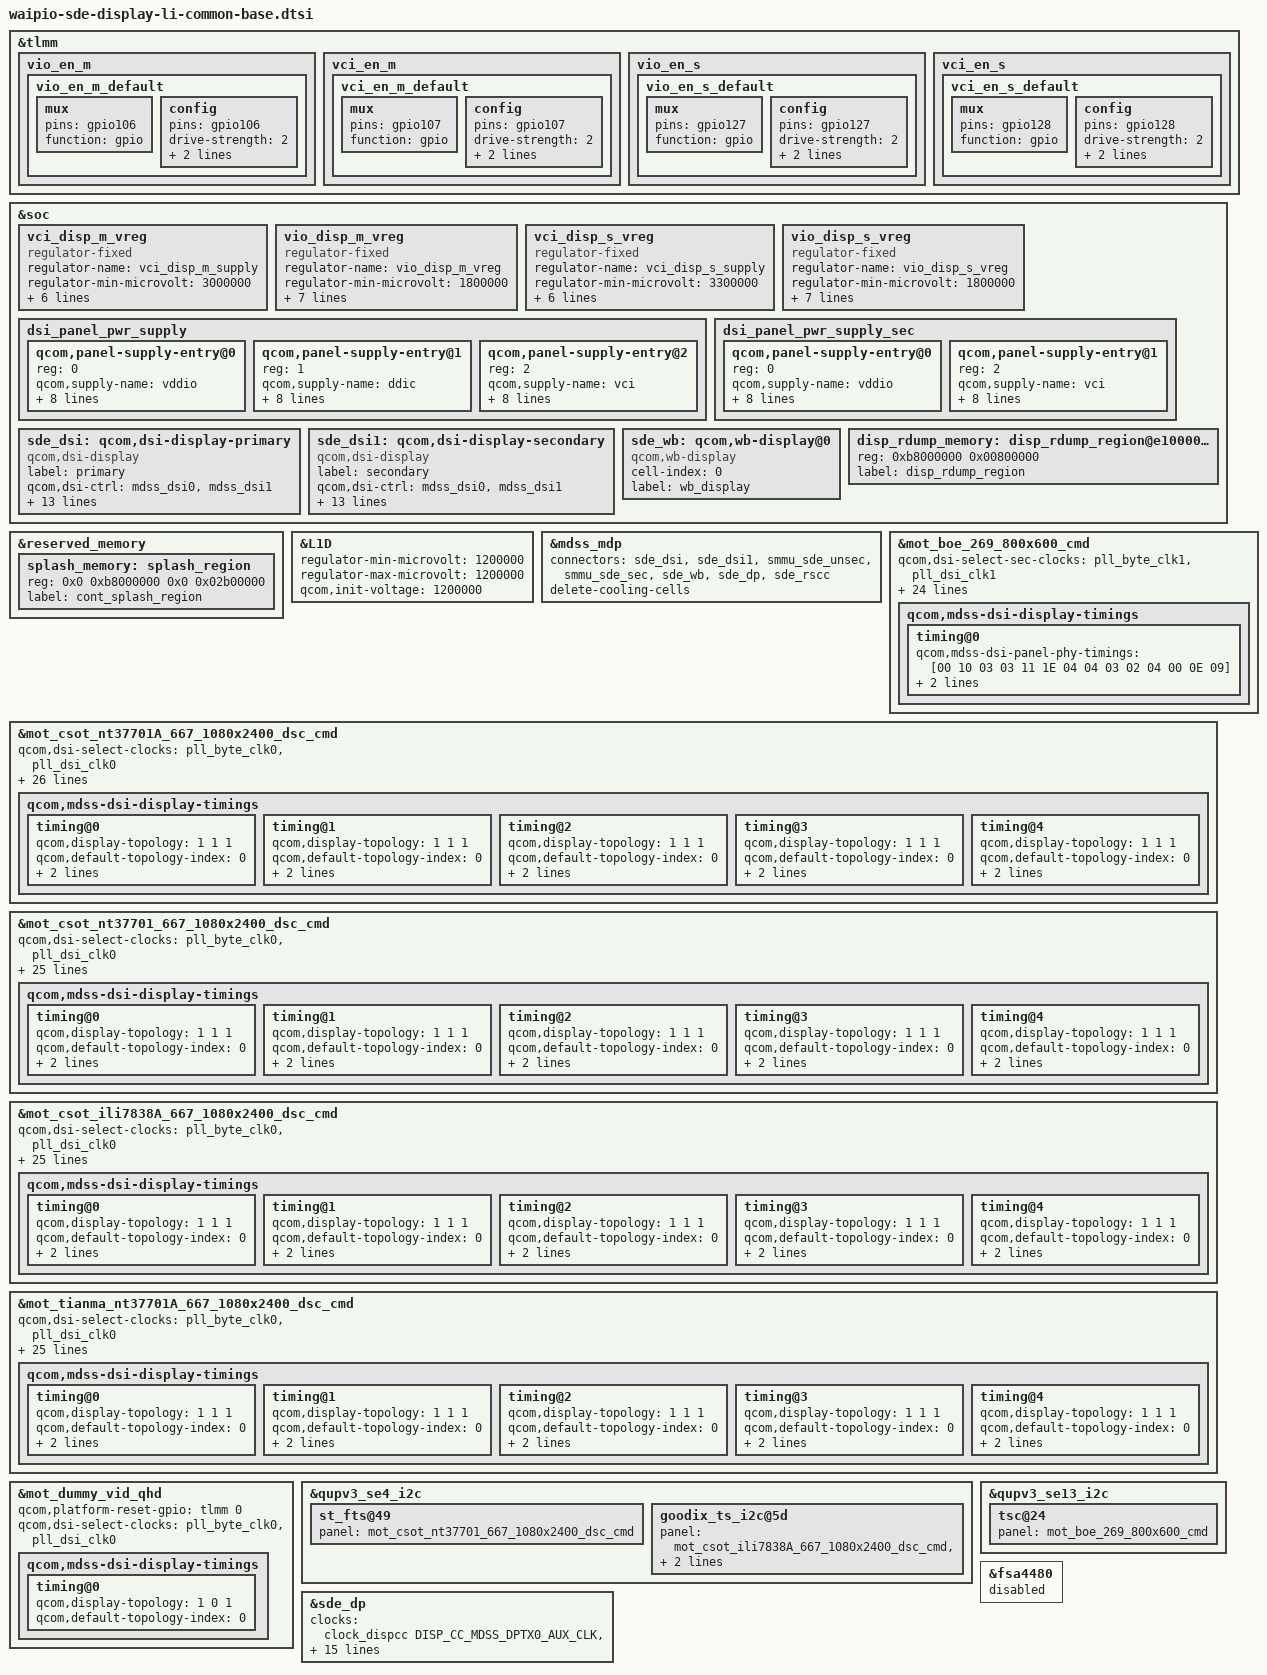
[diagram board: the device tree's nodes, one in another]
/*
   this is original from waipio-sde-display-hiphi-common-base.dtsi
*/
#include <dt-bindings/clock/qcom,gcc-waipio.h>
#include <dt-bindings/clock/qcom,rpmh.h>
#include "waipio-sde-display-pinctrl.dtsi"
#include "dsi-panel-mot-dummy-qhd-video.dtsi"
#include <dt-bindings/clock/qcom,dispcc-waipio.h>
#include "dsi-panel-mot-csot-nt37701-667-1080x2400-dsc-cmd-common.dtsi"
#include "dsi-panel-mot-csot-ili7838A-667-1080x2400-dsc-cmd-common.dtsi"
#include "dsi-panel-mot-tianma-nt37701A-667-1080x2400-dsc-cmd-common.dtsi"
#include "dsi-panel-mot-csot-nt37701A-667-1080x2400-dsc-cmd-common.dtsi"
#include "dsi-panel-mot-boe-269-800x600-cmd-common.dtsi"

&tlmm {
	vio_en_m {
		vio_en_m_default: vio_en_m_default {
			mux {
				pins = "gpio106";
				function = "gpio";
			};

			config {
				pins = "gpio106";
				drive-strength = <2>;   /* 2 mA */
				bias-disable = <0>;   /* no pull */
				output-high;
			};
		};
	};
	vci_en_m {
		vci_en_m_default: vci_en_m_default {
			mux {
				pins = "gpio107";
				function = "gpio";
			};

			config {
				pins = "gpio107";
				drive-strength = <2>;   /* 2 mA */
				bias-disable = <0>;   /* no pull */
				output-enable;
			};
		};
	};
	vio_en_s {
		vio_en_s_default: vio_en_s_default {
			mux {
				pins = "gpio127";
				function = "gpio";
			};

			config {
				pins = "gpio127";
				drive-strength = <2>;   /* 2 mA */
				bias-disable = <0>;   /* no pull */
				output-high;
			};
		};
	};
	vci_en_s {
		vci_en_s_default: vci_en_s_default {
			mux {
				pins = "gpio128";
				function = "gpio";
			};

			config {
				pins = "gpio128";
				drive-strength = <2>;   /* 2 mA */
				bias-disable = <0>;   /* no pull */
				output-enable;
			};
		};
	};
};

&soc {
	vci_disp_m_vreg:  vci_disp_m_vreg{
		compatible = "regulator-fixed";
		regulator-name = "vci_disp_m_supply";
		regulator-min-microvolt = <3000000>;
		regulator-max-microvolt = <3000000>;
		enable-active-high;
		regulator-boot-on;

		gpio = <&tlmm 107 0>;
		pinctrl-names = "default";
		pinctrl-0 = <&vci_en_m_default>;
		vin-supply = <&L13C>;
	};

	vio_disp_m_vreg: vio_disp_m_vreg{
		compatible = "regulator-fixed";
		regulator-name = "vio_disp_m_vreg";
		regulator-min-microvolt = <1800000>;
		regulator-max-microvolt = <1800000>;
		regulator-enable-ramp-delay = <233>;
		enable-active-high;
		regulator-boot-on;

		gpio = <&tlmm 106 0>;
		pinctrl-names = "default";
		pinctrl-0 = <&vio_en_m_default>;
		vin-supply = <&L12C>;
	};

	vci_disp_s_vreg:  vci_disp_s_vreg{
		compatible = "regulator-fixed";
		regulator-name = "vci_disp_s_supply";
		regulator-min-microvolt = <3300000>;
		regulator-max-microvolt = <3300000>;
		enable-active-high;
		regulator-boot-on;

		gpio = <&tlmm 128 0>;
		pinctrl-names = "default";
		pinctrl-0 = <&vci_en_s_default>;
		vin-supply = <&L3C>;
	};

	vio_disp_s_vreg: vio_disp_s_vreg{
		compatible = "regulator-fixed";
		regulator-name = "vio_disp_s_vreg";
		regulator-min-microvolt = <1800000>;
		regulator-max-microvolt = <1800000>;
		regulator-enable-ramp-delay = <233>;
		enable-active-high;
		regulator-boot-on;

		gpio = <&tlmm 127 0>;
		pinctrl-names = "default";
		pinctrl-0 = <&vio_en_s_default>;
		vin-supply = <&L2C>;
	};


	dsi_panel_pwr_supply: dsi_panel_pwr_supply {
		#address-cells = <1>;
		#size-cells = <0>;

	qcom,panel-supply-entry@0 {
		reg = <0>;
		qcom,supply-name = "vddio";
		qcom,supply-min-voltage = <1800000>;
		qcom,supply-max-voltage = <1800000>;
		qcom,supply-enable-load = <300000>;
		qcom,supply-disable-load = <100>;
		qcom,supply-pre-on-sleep = <0>;
		qcom,supply-post-on-sleep = <1>;
		qcom,supply-pre-off-sleep = <3>;
		qcom,supply-post-off-sleep = <0>;
        };

        qcom,panel-supply-entry@1 {
		reg = <1>;
		qcom,supply-name = "ddic";
		qcom,supply-min-voltage = <1200000>;
		qcom,supply-max-voltage = <1200000>;
		qcom,supply-enable-load = <300000>;
		qcom,supply-disable-load = <0>;
		qcom,supply-pre-on-sleep = <1>;
		qcom,supply-post-on-sleep = <0>;
		qcom,supply-pre-off-sleep = <2>;
		qcom,supply-post-off-sleep = <0>;
        };
        qcom,panel-supply-entry@2 {
		reg = <2>;
		qcom,supply-name = "vci";
		qcom,supply-min-voltage = <3000000>;
		qcom,supply-max-voltage = <3000000>;
		qcom,supply-enable-load = <300000>;
		qcom,supply-disable-load = <0>;
		qcom,supply-pre-on-sleep = <0>;
		qcom,supply-post-on-sleep = <0>;
		qcom,supply-pre-off-sleep = <2>;
		qcom,supply-post-off-sleep = <0>;
        };
	};

	dsi_panel_pwr_supply_sec: dsi_panel_pwr_supply_sec {
		#address-cells = <1>;
		#size-cells = <0>;

	qcom,panel-supply-entry@0 {
		reg = <0>;
		qcom,supply-name = "vddio";
		qcom,supply-min-voltage = <1800000>;
		qcom,supply-max-voltage = <1800000>;
		qcom,supply-enable-load = <300000>;
		qcom,supply-disable-load = <100>;
		qcom,supply-pre-on-sleep = <0>;
		qcom,supply-post-on-sleep = <1>;
		qcom,supply-pre-off-sleep = <3>;
		qcom,supply-post-off-sleep = <0>;
        };

        qcom,panel-supply-entry@1 {
		reg = <2>;
		qcom,supply-name = "vci";
		qcom,supply-min-voltage = <3300000>;
		qcom,supply-max-voltage = <3300000>;
		qcom,supply-enable-load = <300000>;
		qcom,supply-disable-load = <0>;
		qcom,supply-pre-on-sleep = <0>;
		qcom,supply-post-on-sleep = <0>;
		qcom,supply-pre-off-sleep = <2>;
		qcom,supply-post-off-sleep = <0>;
        };
	};
	sde_dsi: qcom,dsi-display-primary {
		compatible = "qcom,dsi-display";
		label = "primary";

		qcom,dsi-ctrl = <&mdss_dsi0 &mdss_dsi1>;
		qcom,dsi-phy = <&mdss_dsi_phy0 &mdss_dsi_phy1>;

		pinctrl-names = "panel_active", "panel_suspend";
		pinctrl-0 = <&sde_dsi_active &sde_te_active>;
		pinctrl-1 = <&sde_dsi_suspend &sde_te_suspend>;

		qcom,platform-te-gpio = <&tlmm 86 0>;
		qcom,panel-te-source = <0>;

		qcom,mdp = <&mdss_mdp>;
		qcom,dsi-default-panel = <&mot_dummy_vid_qhd>;
	};

	sde_dsi1: qcom,dsi-display-secondary {
		compatible = "qcom,dsi-display";
		label = "secondary";

		qcom,dsi-ctrl = <&mdss_dsi0 &mdss_dsi1>;
		qcom,dsi-phy = <&mdss_dsi_phy0 &mdss_dsi_phy1>;

		pinctrl-names = "panel_active", "panel_suspend";
		pinctrl-0 = <&sde_dsi1_active &sde_te1_active>;
		pinctrl-1 = <&sde_dsi1_suspend &sde_te1_suspend>;

		qcom,platform-te-gpio = <&tlmm 124 0>;
		qcom,panel-te-source = <1>;

		qcom,mdp = <&mdss_mdp>;
		qcom,dsi-default-panel = <&mot_boe_269_800x600_cmd>;
	};
};


&soc {
	/*display_panel_avdd: display_gpio_regulator@1 {
		compatible = "qti-regulator-fixed";
		regulator-name = "display_panel_avdd";
		regulator-min-microvolt = <5500000>;
		regulator-max-microvolt = <5500000>;
		regulator-enable-ramp-delay = <233>;
		gpio = <&tlmm 64 0>;
		enable-active-high;
		regulator-boot-on;
		proxy-supply = <&display_panel_avdd>;
		qcom,proxy-consumer-enable;
		pinctrl-names = "default";
		pinctrl-0 = <&display_panel_avdd_default>;
	};*/

	sde_wb: qcom,wb-display@0 {
		compatible = "qcom,wb-display";
		cell-index = <0>;
		label = "wb_display";
	};

	disp_rdump_memory: disp_rdump_region@e1000000 {
		reg = <0xb8000000 0x00800000>;
		label = "disp_rdump_region";
	};

};

&reserved_memory {
	splash_memory: splash_region {
		reg = <0x0 0xb8000000 0x0 0x02b00000>;
		label = "cont_splash_region";
	};
};

&sde_dsi {
	clocks = <&mdss_dsi_phy0 0>,
			<&mdss_dsi_phy0 1>,
			<&mdss_dsi_phy1 2>,
			<&mdss_dsi_phy1 3>,
			 /*
			  * Currently the dsi clock handles are under the dsi
			  * controller DT node. As soon as the controller probe
			  * finishes, the dispcc sync state can get called before
			  * the dsi_display probe potentially disturbing the clock
			  * votes for cont_splash use case. Hence we are no longer
			  * protected by the component model in this case against the
			  * disp cc sync state getting triggered after the dsi_ctrl
			  * probe. To protect against this incorrect sync state trigger
			  * add this dummy MDP clk vote handle to the dsi_display
			  * DT node. Since the dsi_display driver does not parse
			  * MDP clock nodes, no actual vote shall be added and this
			  * change is done just to satisfy sync state requirements.
			  */
			 <&clock_dispcc DISP_CC_MDSS_MDP_CLK>;
	clock-names = "pll_byte_clk0", "pll_dsi_clk0",
			"pll_byte_clk1", "pll_dsi_clk1",
			"mdp_core_clk";

	pinctrl-names = "panel_active", "panel_suspend";
	pinctrl-0 = <&sde_dsi_active &sde_te_active>;
	pinctrl-1 = <&sde_dsi_suspend &sde_te_suspend>;

	qcom,platform-te-gpio = <&tlmm 86 0>;
	qcom,panel-te-source = <0>;

	vddio-supply = <&vio_disp_m_vreg>;
	ddic-supply = <&L1D>;
	vci-supply = <&vci_disp_m_vreg>;
};

&sde_dsi1 {
	clocks = <&mdss_dsi_phy0 0>,
			<&mdss_dsi_phy0 1>,
			<&mdss_dsi_phy1 2>,
			<&mdss_dsi_phy1 3>,
			 /*
			  * Currently the dsi clock handles are under the dsi
			  * controller DT node. As soon as the controller probe
			  * finishes, the dispcc sync state can get called before
			  * the dsi_display probe potentially disturbing the clock
			  * votes for cont_splash use case. Hence we are no longer
			  * protected by the component model in this case against the
			  * disp cc sync state getting triggered after the dsi_ctrl
			  * probe. To protect against this incorrect sync state trigger
			  * add this dummy MDP clk vote handle to the dsi_display
			  * DT node. Since the dsi_display driver does not parse
			  * MDP clock nodes, no actual vote shall be added and this
			  * change is done just to satisfy sync state requirements.
			  */
			 <&clock_dispcc DISP_CC_MDSS_MDP_CLK>;
	clock-names = "pll_byte_clk0", "pll_dsi_clk0",
			"pll_byte_clk1", "pll_dsi_clk1",
			"mdp_core_clk";

	pinctrl-names = "panel_active", "panel_suspend";
	pinctrl-0 = <&sde_dsi1_active &sde_te1_active>;
	pinctrl-1 = <&sde_dsi1_suspend &sde_te1_suspend>;

	qcom,platform-te-gpio = <&tlmm 124 0>;
	qcom,panel-te-source = <1>;

	vddio-supply = <&vio_disp_s_vreg>;
	vci-supply = <&vci_disp_s_vreg>;
};

&L1D {
	regulator-min-microvolt = <1200000>;
	regulator-max-microvolt = <1200000>;
	qcom,init-voltage = <1200000>;
};

&mdss_mdp {
	connectors = <&sde_dsi &sde_dsi1 &smmu_sde_unsec &smmu_sde_sec &sde_wb &sde_dp &sde_rscc>;
	delete-cooling-cells;
};


&mot_boe_269_800x600_cmd {
	qcom,dsi-select-sec-clocks = "pll_byte_clk1", "pll_dsi_clk1";

	qcom,panel-supply-entries = <&dsi_panel_pwr_supply>;
	qcom,panel-sec-supply-entries = <&dsi_panel_pwr_supply_sec>;
	qcom,mdss-dsi-bl-pmic-control-type = "bl_ctrl_dcs";
	qcom,mdss-dsi-sec-bl-pmic-control-type = "bl_ctrl_dcs";
	qcom,mdss-dsi-bl-min-level = <3>;
	qcom,mdss-dsi-bl-max-level = <255>;
	qcom,mdss-brightness-max-level = <255>;
	qcom,platform-sec-reset-gpio = <&tlmm 123 0>;
	qcom,mdss-dsi-panel-orientation = "180";
	qcom,mdss-dsi-panel-status-check-mode = "reg_read";
	qcom,mdss-dsi-panel-status-command = [06 01 00 01 00 00 01 0a];
	qcom,mdss-dsi-panel-status-command-state = "dsi_lp_mode";
	qcom,mdss-dsi-panel-status-value = <0x9c>;
	qcom,mdss-dsi-panel-status-read-length = <1>;
	qcom,esd-check-enabled;

	qcom,mdss-dsi-te-using-wd;

        qcom,mdss-dsi-no-panel-on-read-support;

	qcom,mdss-dsi-display-timings {
		timing@0{
			qcom,mdss-dsi-panel-phy-timings = [00 10 03 03 11 1E 04
				04 03 02 04 00 0E 09];
			qcom,display-topology = <1 0 1>;
			qcom,default-topology-index = <0>;
		};
	};
};

&mot_csot_nt37701A_667_1080x2400_dsc_cmd {
	qcom,dsi-select-clocks = "pll_byte_clk0", "pll_dsi_clk0";

	//qcom,dsi-dyn-clk-enable;

	qcom,panel-supply-entries = <&dsi_panel_pwr_supply>;
	qcom,mdss-dsi-no-panel-on-read-support;
	qcom,mdss-dsi-bl-pmic-control-type = "bl_ctrl_dcs";
	qcom,mdss-dsi-bl-min-level = <9>;
	qcom,mdss-dsi-bl-max-level = <3515>;
	//qcom,mdss-dsi-bl-default-level = <1024>;
	qcom,mdss-brightness-max-level = <3515>;
	qcom,platform-reset-gpio = <&tlmm 0 0>;
	qcom,bl-dsc-cmd-state = "dsi_hs_mode";
	qcom,mdss-dsi-bl-inverted-dbv;
	qcom,mdss-dsi-bl-is-exponent;

	qcom,mdss-dsi-panel-hdr-enabled;
	qcom,mdss-dsi-panel-hdr-color-primaries = <14950 15750 34000
	        16000 13000 35500 7000 2500>;
	qcom,mdss-dsi-panel-peak-brightness = <5000000>;
	qcom,mdss-dsi-panel-blackness-level = <100>;

	qcom,mdss-dsi-panel-status-check-mode = "reg_read";
	qcom,mdss-dsi-panel-status-command = [06 01 00 01 00 00 01 0a];
	qcom,mdss-dsi-panel-status-command-state = "dsi_lp_mode";
	qcom,mdss-dsi-panel-status-value = <0x9c>;
	qcom,mdss-dsi-panel-status-read-length = <1>;
	qcom,esd-check-enabled;

	qcom,mdss-dsi-display-timings {
		timing@0 {
			//qcom,mdss-dsi-panel-clockrate = <400000000>;
			qcom,display-topology = <1 1 1>;
			qcom,default-topology-index = <0>;
			qcom,mdss-dsi-panel-phy-timings = [00 10 03 03 11 1E 04
							04 03 02 04 00 0E 08];
		};
		timing@1 {
			//qcom,mdss-dsi-panel-clockrate = <601000000>;
			qcom,display-topology = <1 1 1>;
			qcom,default-topology-index = <0>;
			qcom,mdss-dsi-panel-phy-timings = [00 16 05 05 14 1F 06
							06 06 02 04 00 13 0A];
		};
		timing@2 {
			//qcom,mdss-dsi-panel-clockrate = <801000000>;
			qcom,display-topology = <1 1 1>;
			qcom,default-topology-index = <0>;
			qcom,mdss-dsi-panel-phy-timings = [00 1C 07 07 17 15 07
							07 08 02 04 00 18 0C];
		};
		timing@3 {
			//qcom,mdss-dsi-panel-clockrate = <951000000>;
			qcom,display-topology = <1 1 1>;
			qcom,default-topology-index = <0>;
			qcom,mdss-dsi-panel-phy-timings = [00 20 08 08 18 23 08
							08 08 02 04 00 1B 0D];
		};
		timing@4 {
			//qcom,mdss-dsi-panel-clockrate = <320000000>;
			qcom,display-topology = <1 1 1>;
			qcom,default-topology-index = <0>;
			qcom,mdss-dsi-panel-phy-timings = [00 0D 03 03 10 1D 04
							03 02 02 04 00 0C 08];
		};
	};
};
&mot_csot_nt37701_667_1080x2400_dsc_cmd {
	qcom,dsi-select-clocks = "pll_byte_clk0", "pll_dsi_clk0";
	//qcom,dsi-select-sec-clocks = "pll_byte_clk1", "pll_dsi_clk1";

	//qcom,dsi-dyn-clk-enable;

	qcom,panel-supply-entries = <&dsi_panel_pwr_supply>;
	qcom,mdss-dsi-no-panel-on-read-support;
	qcom,mdss-dsi-bl-pmic-control-type = "bl_ctrl_dcs";
	qcom,mdss-dsi-bl-min-level = <9>;
	qcom,mdss-dsi-bl-max-level = <2047>;
	//qcom,mdss-dsi-bl-default-level = <1024>;
	qcom,mdss-brightness-max-level = <2047>;
	qcom,platform-reset-gpio = <&tlmm 0 0>;
	qcom,bl-dsc-cmd-state = "dsi_hs_mode";
	qcom,mdss-dsi-bl-inverted-dbv;

	qcom,mdss-dsi-panel-hdr-enabled;
	qcom,mdss-dsi-panel-hdr-color-primaries = <14950 15750 34000
	        16000 13000 35500 7000 2500>;
	qcom,mdss-dsi-panel-peak-brightness = <5000000>;
	qcom,mdss-dsi-panel-blackness-level = <100>;

	qcom,mdss-dsi-panel-status-check-mode = "reg_read";
	qcom,mdss-dsi-panel-status-command = [06 01 00 01 00 00 01 0a];
	qcom,mdss-dsi-panel-status-command-state = "dsi_lp_mode";
	qcom,mdss-dsi-panel-status-value = <0x9c>;
	qcom,mdss-dsi-panel-status-read-length = <1>;
	qcom,esd-check-enabled;

	qcom,mdss-dsi-display-timings {
		timing@0 {
			//qcom,mdss-dsi-panel-clockrate = <400000000>;
			qcom,display-topology = <1 1 1>;
			qcom,default-topology-index = <0>;
			qcom,mdss-dsi-panel-phy-timings = [00 10 03 03 11 1E 04
							04 03 02 04 00 0E 08];
		};
		timing@1 {
			//qcom,mdss-dsi-panel-clockrate = <601000000>;
			qcom,display-topology = <1 1 1>;
			qcom,default-topology-index = <0>;
			qcom,mdss-dsi-panel-phy-timings = [00 16 05 05 14 1F 06
							06 06 02 04 00 13 0A];
		};
		timing@2 {
			//qcom,mdss-dsi-panel-clockrate = <801000000>;
			qcom,display-topology = <1 1 1>;
			qcom,default-topology-index = <0>;
			qcom,mdss-dsi-panel-phy-timings = [00 1C 07 07 17 15 07
							07 08 02 04 00 18 0C];
		};
		timing@3 {
			//qcom,mdss-dsi-panel-clockrate = <951000000>;
			qcom,display-topology = <1 1 1>;
			qcom,default-topology-index = <0>;
			qcom,mdss-dsi-panel-phy-timings = [00 20 08 08 18 23 08
							08 08 02 04 00 1B 0D];
		};
		timing@4 {
			//qcom,mdss-dsi-panel-clockrate = <320000000>;
			qcom,display-topology = <1 1 1>;
			qcom,default-topology-index = <0>;
			qcom,mdss-dsi-panel-phy-timings = [00 0D 03 03 10 1D 04
							03 02 02 04 00 0C 08];
		};
	};
};

&mot_csot_ili7838A_667_1080x2400_dsc_cmd {
	qcom,dsi-select-clocks = "pll_byte_clk0", "pll_dsi_clk0";
	//qcom,dsi-select-sec-clocks = "pll_byte_clk1", "pll_dsi_clk1";

	//qcom,dsi-dyn-clk-enable;

	qcom,panel-supply-entries = <&dsi_panel_pwr_supply>;
	qcom,mdss-dsi-no-panel-on-read-support;
	qcom,mdss-dsi-bl-pmic-control-type = "bl_ctrl_dcs";
	qcom,mdss-dsi-bl-min-level = <9>;
	qcom,mdss-dsi-bl-max-level = <2047>;
	//qcom,mdss-dsi-bl-default-level = <1024>;
	qcom,mdss-brightness-max-level = <2047>;
	qcom,platform-reset-gpio = <&tlmm 0 0>;
	qcom,bl-dsc-cmd-state = "dsi_hs_mode";
	qcom,mdss-dsi-bl-inverted-dbv;

	qcom,mdss-dsi-panel-hdr-enabled;
	qcom,mdss-dsi-panel-hdr-color-primaries = <14950 15750 34000
	        16000 13000 35500 7000 2500>;
	qcom,mdss-dsi-panel-peak-brightness = <5000000>;
	qcom,mdss-dsi-panel-blackness-level = <100>;

	qcom,mdss-dsi-panel-status-check-mode = "reg_read";
	qcom,mdss-dsi-panel-status-command = [06 01 00 01 00 00 01 0a];
	qcom,mdss-dsi-panel-status-command-state = "dsi_lp_mode";
	qcom,mdss-dsi-panel-status-value = <0x9c>;
	qcom,mdss-dsi-panel-status-read-length = <1>;
	qcom,esd-check-enabled;

	qcom,mdss-dsi-display-timings {
		timing@0 {
			//qcom,mdss-dsi-panel-clockrate = <400000000>;
			qcom,display-topology = <1 1 1>;
			qcom,default-topology-index = <0>;
			qcom,mdss-dsi-panel-phy-timings = [00 10 03 03 11 1E 04
							04 03 02 04 00 0E 08];
		};
		timing@1 {
			//qcom,mdss-dsi-panel-clockrate = <601000000>;
			qcom,display-topology = <1 1 1>;
			qcom,default-topology-index = <0>;
			qcom,mdss-dsi-panel-phy-timings = [00 16 05 05 14 1F 06
							06 06 02 04 00 13 0A];
		};
		timing@2 {
			//qcom,mdss-dsi-panel-clockrate = <801000000>;
			qcom,display-topology = <1 1 1>;
			qcom,default-topology-index = <0>;
			qcom,mdss-dsi-panel-phy-timings = [00 1C 07 07 17 15 07
							07 08 02 04 00 18 0C];
		};
		timing@3 {
			//qcom,mdss-dsi-panel-clockrate = <951000000>;
			qcom,display-topology = <1 1 1>;
			qcom,default-topology-index = <0>;
			qcom,mdss-dsi-panel-phy-timings = [00 20 08 08 18 23 08
							08 08 02 04 00 1B 0D];
		};
		timing@4 {
			//qcom,mdss-dsi-panel-clockrate = <320000000>;
			qcom,display-topology = <1 1 1>;
			qcom,default-topology-index = <0>;
			qcom,mdss-dsi-panel-phy-timings = [00 0D 03 03 10 1D 04
							03 02 02 04 00 0C 08];
		};
	};
};

&mot_tianma_nt37701A_667_1080x2400_dsc_cmd {
	qcom,dsi-select-clocks = "pll_byte_clk0", "pll_dsi_clk0";
	//qcom,dsi-select-sec-clocks = "pll_byte_clk1", "pll_dsi_clk1";

	//qcom,dsi-dyn-clk-enable;

	qcom,panel-supply-entries = <&dsi_panel_pwr_supply>;
	qcom,mdss-dsi-no-panel-on-read-support;
	qcom,mdss-dsi-bl-pmic-control-type = "bl_ctrl_dcs";
	qcom,mdss-dsi-bl-min-level = <9>;
	qcom,mdss-dsi-bl-max-level = <3197>;
	//qcom,mdss-dsi-bl-default-level = <1024>;
	qcom,mdss-brightness-max-level = <3197>;
	qcom,platform-reset-gpio = <&tlmm 0 0>;
	qcom,bl-dsc-cmd-state = "dsi_hs_mode";
	qcom,mdss-dsi-bl-inverted-dbv;

	qcom,mdss-dsi-panel-hdr-enabled;
	qcom,mdss-dsi-panel-hdr-color-primaries = <14950 15750 34000
	        16000 13000 35500 7000 2500>;
	qcom,mdss-dsi-panel-peak-brightness = <5000000>;
	qcom,mdss-dsi-panel-blackness-level = <100>;

	qcom,mdss-dsi-panel-status-check-mode = "reg_read";
	qcom,mdss-dsi-panel-status-command = [06 01 00 01 00 00 01 0a];
	qcom,mdss-dsi-panel-status-command-state = "dsi_lp_mode";
	qcom,mdss-dsi-panel-status-value = <0x9c>;
	qcom,mdss-dsi-panel-status-read-length = <1>;
	qcom,esd-check-enabled;

	qcom,mdss-dsi-display-timings {
		timing@0 {
			//qcom,mdss-dsi-panel-clockrate = <400000000>;
			qcom,display-topology = <1 1 1>;
			qcom,default-topology-index = <0>;
			qcom,mdss-dsi-panel-phy-timings = [00 10 03 03 11 1E 04
							04 03 02 04 00 0E 08];
		};
		timing@1 {
			//qcom,mdss-dsi-panel-clockrate = <601000000>;
			qcom,display-topology = <1 1 1>;
			qcom,default-topology-index = <0>;
			qcom,mdss-dsi-panel-phy-timings = [00 16 05 05 14 1F 06
							06 06 02 04 00 13 0A];
		};
		timing@2 {
			//qcom,mdss-dsi-panel-clockrate = <801000000>;
			qcom,display-topology = <1 1 1>;
			qcom,default-topology-index = <0>;
			qcom,mdss-dsi-panel-phy-timings = [00 1C 07 07 17 15 07
							07 08 02 04 00 18 0C];
		};
		timing@3 {
			//qcom,mdss-dsi-panel-clockrate = <951000000>;
			qcom,display-topology = <1 1 1>;
			qcom,default-topology-index = <0>;
			qcom,mdss-dsi-panel-phy-timings = [00 20 08 08 18 23 08
							08 08 02 04 00 1B 0D];
		};
		timing@4 {
			//qcom,mdss-dsi-panel-clockrate = <320000000>;
			qcom,display-topology = <1 1 1>;
			qcom,default-topology-index = <0>;
			qcom,mdss-dsi-panel-phy-timings = [00 0D 03 03 10 1D 04
							03 02 02 04 00 0C 08];
		};
	};
};
&mot_dummy_vid_qhd {
	qcom,platform-reset-gpio = <&tlmm 0 0>;

	qcom,dsi-select-clocks = "pll_byte_clk0", "pll_dsi_clk0";
	qcom,mdss-dsi-display-timings {
		timing@0 {
			qcom,display-topology = <1 0 1>;
			qcom,default-topology-index = <0>;
		};
	};
};

&sde_dsi {
	qcom,dsi-default-panel = <&mot_dummy_vid_qhd>;
};

&qupv3_se4_i2c {
	st_fts@49 {
		panel = <&mot_csot_nt37701_667_1080x2400_dsc_cmd>;
	};

	goodix_ts_i2c@5d {
		panel = <&mot_csot_ili7838A_667_1080x2400_dsc_cmd
			&mot_tianma_nt37701A_667_1080x2400_dsc_cmd
			&mot_csot_nt37701A_667_1080x2400_dsc_cmd>;
	};
};

&qupv3_se13_i2c {
	tsc@24 {
		panel = <&mot_boe_269_800x600_cmd>;
	};
};

&fsa4480 {
	status = "disabled";
};

&sde_dp {
	#clock-cells = <1>;
	clocks =  <&clock_dispcc DISP_CC_MDSS_DPTX0_AUX_CLK>,
		<&clock_rpmh RPMH_CXO_CLK>,
		<&clock_gcc GCC_USB3_0_CLKREF_EN>,
		<&clock_gcc GCC_USB3_PRIM_PHY_PIPE_CLK>,
		<&clock_dispcc DISP_CC_MDSS_DPTX0_LINK_CLK>,
		<&clock_dispcc DISP_CC_MDSS_DPTX0_LINK_CLK_SRC>,
		<&clock_dispcc DISP_CC_MDSS_DPTX0_LINK_INTF_CLK>,
		<&clock_dispcc DISP_CC_MDSS_DPTX0_PIXEL0_CLK_SRC>,
		<&sde_dp 1>,
		<&clock_dispcc DISP_CC_MDSS_DPTX0_PIXEL1_CLK_SRC>,
		<&clock_dispcc DISP_CC_MDSS_DPTX0_PIXEL0_CLK>,
		<&clock_dispcc DISP_CC_MDSS_DPTX0_PIXEL1_CLK>;
	clock-names = "core_aux_clk", "rpmh_cxo_clk", "core_usb_ref_clk_src",
		"core_usb_pipe_clk", "link_clk", "link_clk_src", "link_iface_clk",
		"pixel_clk_rcg", "pixel_parent", "pixel1_clk_rcg",
		"strm0_pixel_clk", "strm1_pixel_clk";
	clock-mmrm = <0 0 0 0 0 DISP_CC_MDSS_DPTX0_LINK_CLK_SRC 0 0 0 0 0 0>;

	mmi,aux-switch-enable-gpio = <&tlmm 2 0x00>;
	mmi,aux-switch-flip-gpio = <&tlmm 71 0x00>;
};
